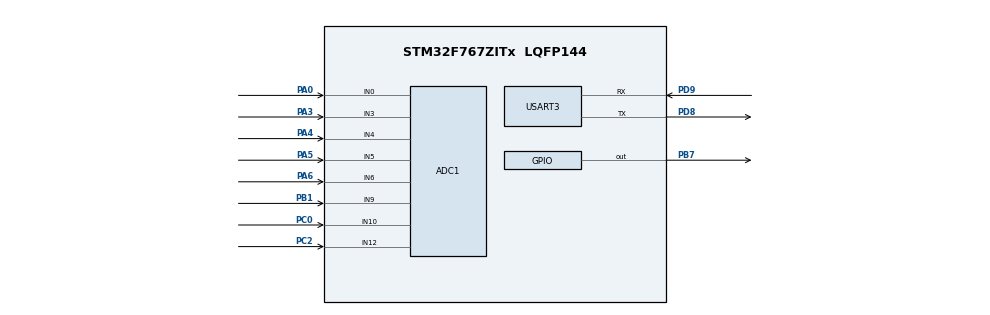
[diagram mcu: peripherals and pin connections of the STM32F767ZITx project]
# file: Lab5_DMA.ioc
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ADC1.Channel-0\#ChannelRegularConversion=ADC_CHANNEL_0
ADC1.Channel-1\#ChannelRegularConversion=ADC_CHANNEL_3
ADC1.Channel-2\#ChannelRegularConversion=ADC_CHANNEL_4
ADC1.Channel-3\#ChannelRegularConversion=ADC_CHANNEL_5
ADC1.Channel-4\#ChannelRegularConversion=ADC_CHANNEL_6
ADC1.Channel-5\#ChannelRegularConversion=ADC_CHANNEL_9
ADC1.Channel-6\#ChannelRegularConversion=ADC_CHANNEL_10
ADC1.Channel-7\#ChannelRegularConversion=ADC_CHANNEL_12
ADC1.ContinuousConvMode=ENABLE
ADC1.DMAContinuousRequests=ENABLE
ADC1.NbrOfConversion=8
ADC1.NbrOfConversionFlag=1
ADC1.Rank-0\#ChannelRegularConversion=1
ADC1.Rank-1\#ChannelRegularConversion=2
ADC1.Rank-2\#ChannelRegularConversion=3
ADC1.Rank-3\#ChannelRegularConversion=4
ADC1.Rank-4\#ChannelRegularConversion=5
ADC1.Rank-5\#ChannelRegularConversion=6
ADC1.Rank-6\#ChannelRegularConversion=7
ADC1.Rank-7\#ChannelRegularConversion=8
ADC1.SamplingTime-0\#ChannelRegularConversion=ADC_SAMPLETIME_3CYCLES
ADC1.SamplingTime-1\#ChannelRegularConversion=ADC_SAMPLETIME_3CYCLES
ADC1.SamplingTime-2\#ChannelRegularConversion=ADC_SAMPLETIME_3CYCLES
ADC1.SamplingTime-3\#ChannelRegularConversion=ADC_SAMPLETIME_3CYCLES
ADC1.SamplingTime-4\#ChannelRegularConversion=ADC_SAMPLETIME_3CYCLES
ADC1.SamplingTime-5\#ChannelRegularConversion=ADC_SAMPLETIME_3CYCLES
ADC1.SamplingTime-6\#ChannelRegularConversion=ADC_SAMPLETIME_3CYCLES
ADC1.SamplingTime-7\#ChannelRegularConversion=ADC_SAMPLETIME_3CYCLES
ADC1.ScanConvMode=ADC_SCAN_ENABLE
ADC1.master=1
CORTEX_M7.default_mode_Activation=1
Dma.ADC1.0.Direction=DMA_PERIPH_TO_MEMORY
Dma.ADC1.0.FIFOMode=DMA_FIFOMODE_DISABLE
Dma.ADC1.0.Instance=DMA2_Stream0
Dma.ADC1.0.MemDataAlignment=DMA_MDATAALIGN_WORD
Dma.ADC1.0.MemInc=DMA_MINC_ENABLE
Dma.ADC1.0.Mode=DMA_CIRCULAR
Dma.ADC1.0.PeriphDataAlignment=DMA_PDATAALIGN_WORD
Dma.ADC1.0.PeriphInc=DMA_PINC_DISABLE
Dma.ADC1.0.Priority=DMA_PRIORITY_LOW
Dma.Request0=ADC1
Mcu.Family=STM32F7
Mcu.Name=STM32F767ZITx
Mcu.Package=LQFP144
NVIC.DMA2_Stream0_IRQn=true\:1\:0\:true\:false\:true\:false\:true\:true
NVIC.PriorityGroup=NVIC_PRIORITYGROUP_2
PA0/WKUP.Signal=ADCx_IN0
PA3.Signal=ADCx_IN3
PA4.Signal=ADCx_IN4
PA5.Signal=ADCx_IN5
PA6.Signal=ADCx_IN6
PB1.Signal=ADCx_IN9
PB7.Signal=GPIO_Output
PC0.Signal=ADCx_IN10
PC2.Signal=ADCx_IN12
PD8.Mode=Asynchronous
PD8.Signal=USART3_TX
PD9.Mode=Asynchronous
PD9.Signal=USART3_RX
ProjectManager.HeapSize=0x200
ProjectManager.StackSize=0x400
ProjectManager.TargetToolchain=STM32CubeIDE
RCC.HSE_VALUE=25000000
RCC.HSI_VALUE=16000000
RCC.LSE_VALUE=32768
RCC.USBFreq_Value=96000000
RCC.VCOOutputFreq_Value=192000000
SH.ADCx_IN0.0=ADC1_IN0,IN0
SH.ADCx_IN10.0=ADC1_IN10,IN10
SH.ADCx_IN12.0=ADC1_IN12,IN12
SH.ADCx_IN3.0=ADC1_IN3,IN3
SH.ADCx_IN4.0=ADC1_IN4,IN4
SH.ADCx_IN5.0=ADC1_IN5,IN5
SH.ADCx_IN6.0=ADC1_IN6,IN6
SH.ADCx_IN9.0=ADC1_IN9,IN9
USART3.VirtualMode-Asynchronous=VM_ASYNC
board=custom

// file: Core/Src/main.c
/* USER CODE BEGIN Header */
/**
  ******************************************************************************
  * @file           : main.c
  * @brief          : Main program body
  ******************************************************************************
  * @attention
  *
  * Copyright (c) 2025 STMicroelectronics.
  * All rights reserved.
  *
  * This software is licensed under terms that can be found in the LICENSE file
  * in the root directory of this software component.
  * If no LICENSE file comes with this software, it is provided AS-IS.
  *
  ******************************************************************************
  */
/* USER CODE END Header */
#include "main.h"
#include "adc.h"
#include "dma.h"
#include "usart.h"
#include "gpio.h"

/* USER CODE BEGIN Includes */
#include <stdio.h>
#include <string.h>
/* USER CODE END Includes */

/* USER CODE BEGIN PV */
int delayTime = 400;
uint32_t adc_val[8];
/* USER CODE END PV */

void SystemClock_Config(void);
static void MPU_Config(void);

int main(void)
{

  /* MPU Configuration--------------------------------------------------------*/
  MPU_Config();

  /* MCU Configuration--------------------------------------------------------*/

  /* Reset of all peripherals, Initializes the Flash interface and the Systick. */
  HAL_Init();

  /* Configure the system clock */
  SystemClock_Config();

  /* Initialize all configured peripherals */
  MX_GPIO_Init();
  MX_DMA_Init();
  MX_ADC1_Init();
  MX_USART3_UART_Init();

  /* Infinite loop */
  /* USER CODE BEGIN WHILE */
  HAL_ADC_Start_DMA(&hadc1, adc_val, 8);
  while (1)
  {
    /* USER CODE END WHILE */

  }
}

void SystemClock_Config(void)
{
  RCC_OscInitTypeDef RCC_OscInitStruct = {0};
  RCC_ClkInitTypeDef RCC_ClkInitStruct = {0};

  /** Configure the main internal regulator output voltage
  */
  __HAL_RCC_PWR_CLK_ENABLE();
  __HAL_PWR_VOLTAGESCALING_CONFIG(PWR_REGULATOR_VOLTAGE_SCALE3);

  /** Initializes the RCC Oscillators according to the specified parameters
  * in the RCC_OscInitTypeDef structure.
  */
  RCC_OscInitStruct.OscillatorType = RCC_OSCILLATORTYPE_HSI;
  RCC_OscInitStruct.HSIState = RCC_HSI_ON;
  RCC_OscInitStruct.HSICalibrationValue = RCC_HSICALIBRATION_DEFAULT;
  RCC_OscInitStruct.PLL.PLLState = RCC_PLL_NONE;
  if (HAL_RCC_OscConfig(&RCC_OscInitStruct) != HAL_OK)
  {
    Error_Handler();
  }

  /** Initializes the CPU, AHB and APB buses clocks
  */
  RCC_ClkInitStruct.ClockType = RCC_CLOCKTYPE_HCLK|RCC_CLOCKTYPE_SYSCLK
                              |RCC_CLOCKTYPE_PCLK1|RCC_CLOCKTYPE_PCLK2;
  RCC_ClkInitStruct.SYSCLKSource = RCC_SYSCLKSOURCE_HSI;
  RCC_ClkInitStruct.AHBCLKDivider = RCC_SYSCLK_DIV1;
  RCC_ClkInitStruct.APB1CLKDivider = RCC_HCLK_DIV1;
  RCC_ClkInitStruct.APB2CLKDivider = RCC_HCLK_DIV1;

  if (HAL_RCC_ClockConfig(&RCC_ClkInitStruct, FLASH_LATENCY_0) != HAL_OK)
  {
    Error_Handler();
  }
}

/* USER CODE BEGIN 4 */
void HAL_ADC_ConvHalfCpltCallback(ADC_HandleTypeDef* hadc){
	HAL_GPIO_WritePin(GPIOB, GPIO_PIN_7, GPIO_PIN_SET);
	HAL_Delay(delayTime);
}

void HAL_ADC_ConvCpltCallback(ADC_HandleTypeDef* hadc){
	HAL_GPIO_WritePin(GPIOB, GPIO_PIN_7, GPIO_PIN_RESET);
	char buf[100];
	sprintf(buf, "0x%08x 0x%08x 0x%08x 0x%08x 0x%08x 0x%08x 0x%08x 0x%08x\r\n", adc_val[0], adc_val[1], adc_val[2], adc_val[3], adc_val[4], adc_val[5], adc_val[6], adc_val[7]);
	HAL_UART_Transmit(&huart3, (uint8_t*)buf, strlen(buf), 200);
	HAL_Delay(delayTime);
}
/* USER CODE END 4 */

 /* MPU Configuration */

void MPU_Config(void)
{
  MPU_Region_InitTypeDef MPU_InitStruct = {0};

  /* Disables the MPU */
  HAL_MPU_Disable();

  /** Initializes and configures the Region and the memory to be protected
  */
  MPU_InitStruct.Enable = MPU_REGION_ENABLE;
  MPU_InitStruct.Number = MPU_REGION_NUMBER0;
  MPU_InitStruct.BaseAddress = 0x0;
  MPU_InitStruct.Size = MPU_REGION_SIZE_4GB;
  MPU_InitStruct.SubRegionDisable = 0x87;
  MPU_InitStruct.TypeExtField = MPU_TEX_LEVEL0;
  MPU_InitStruct.AccessPermission = MPU_REGION_NO_ACCESS;
  MPU_InitStruct.DisableExec = MPU_INSTRUCTION_ACCESS_DISABLE;
  MPU_InitStruct.IsShareable = MPU_ACCESS_SHAREABLE;
  MPU_InitStruct.IsCacheable = MPU_ACCESS_NOT_CACHEABLE;
  MPU_InitStruct.IsBufferable = MPU_ACCESS_NOT_BUFFERABLE;

  HAL_MPU_ConfigRegion(&MPU_InitStruct);
  /* Enables the MPU */
  HAL_MPU_Enable(MPU_PRIVILEGED_DEFAULT);

}

void Error_Handler(void)
{
  __disable_irq();
  while (1)
  {
  }
}
